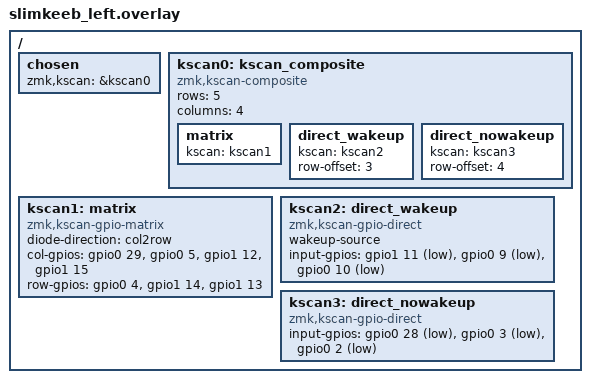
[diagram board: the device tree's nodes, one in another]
#include "slimkeeb.dtsi"

/ {
    chosen {
        zmk,kscan = &kscan0;
    };

    kscan0: kscan_composite {
        compatible = "zmk,kscan-composite";
        rows = <5>;
        columns = <4>;
        matrix {
            kscan = <&kscan1>;
        };
        direct_wakeup {
            kscan = <&kscan2>;
            row-offset = <3>;
        };
        direct_nowakeup {
            kscan = <&kscan3>;
            row-offset = <4>;
        };
    };

    kscan1: matrix {
        compatible = "zmk,kscan-gpio-matrix";
        diode-direction = "col2row";
        col-gpios
            = <&gpio0 29 GPIO_ACTIVE_HIGH>
            , <&gpio0  5 GPIO_ACTIVE_HIGH>
            , <&gpio1 12 GPIO_ACTIVE_HIGH>
            , <&gpio1 15 GPIO_ACTIVE_HIGH>
            ;
        row-gpios
            = <&gpio0  4 (GPIO_ACTIVE_HIGH | GPIO_PULL_DOWN)>
            , <&gpio1 14 (GPIO_ACTIVE_HIGH | GPIO_PULL_DOWN)>
            , <&gpio1 13 (GPIO_ACTIVE_HIGH | GPIO_PULL_DOWN)>
            ;
    };
    kscan2: direct_wakeup {
        compatible = "zmk,kscan-gpio-direct";
        wakeup-source;
        input-gpios =
            <&gpio1 11 (GPIO_ACTIVE_LOW | GPIO_PULL_UP)>,
            <&gpio0  9 (GPIO_ACTIVE_LOW | GPIO_PULL_UP)>,
            <&gpio0 10 (GPIO_ACTIVE_LOW | GPIO_PULL_UP)>;
    };
    kscan3: direct_nowakeup {
        compatible = "zmk,kscan-gpio-direct";
        input-gpios =
            <&gpio0 28 (GPIO_ACTIVE_LOW | GPIO_PULL_UP)>,
            <&gpio0  3 (GPIO_ACTIVE_LOW | GPIO_PULL_UP)>,
            <&gpio0  2 (GPIO_ACTIVE_LOW | GPIO_PULL_UP)>;
    };
};
